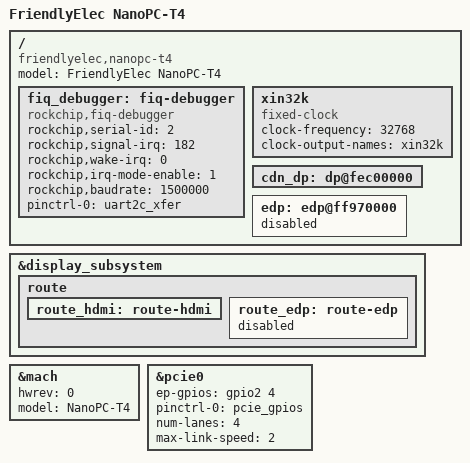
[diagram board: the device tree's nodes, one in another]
/*
 * Copyright (c) 2018 FriendlyElec Computer Tech. Co., Ltd.
 * (http://www.friendlyarm.com)
 *
 * This program is free software; you can redistribute it and/or
 * modify it under the terms of the GNU General Public License
 * as published by the Free Software Foundation; either version 2
 * of the License, or (at your option) any later version.
 *
 * This program is distributed in the hope that it will be useful,
 * but WITHOUT ANY WARRANTY; without even the implied warranty of
 * MERCHANTABILITY or FITNESS FOR A PARTICULAR PURPOSE.  See the
 * GNU General Public License for more details.
 *
 * You should have received a copy of the GNU General Public License
 * along with this program.  If not, see <http://www.gnu.org/licenses/>.
 */

/dts-v1/;
#include "rk3399-nanopi4-common.dtsi"

/ {
	model = "FriendlyElec NanoPC-T4";
	compatible = "friendlyelec,nanopc-t4", "rockchip,rk3399";

	fiq_debugger: fiq-debugger {
		compatible = "rockchip,fiq-debugger";
		rockchip,serial-id = <2>;
		rockchip,signal-irq = <182>;
		rockchip,wake-irq = <0>;
		rockchip,irq-mode-enable = <1>;  /* If enable uart uses irq instead of fiq */
		rockchip,baudrate = <1500000>;  /* Only 115200 and 1500000 */
		pinctrl-names = "default";
		pinctrl-0 = <&uart2c_xfer>;
	};

	xin32k: xin32k {
		compatible = "fixed-clock";
		clock-frequency = <32768>;
		clock-output-names = "xin32k";
		#clock-cells = <0>;
	};

	cdn_dp: dp@fec00000 {
		status = "okay";
	};

	edp: edp@ff970000 {
		status = "disabled";
		/delete-node/ edp_hpd;
	};

};

&display_subsystem {

	route {
		route_hdmi: route-hdmi {
			status = "okay";
		};
		
		route_edp: route-edp {
			status = "disabled";
		};
	};

};

&mach {
	hwrev = <0>;
	model = "NanoPC-T4";
};

&pcie0 {
	ep-gpios = <&gpio2 4 GPIO_ACTIVE_HIGH>;
	pinctrl-names = "default";
	pinctrl-0 = <&pcie_gpios>;
	num-lanes = <4>;
	max-link-speed = <2>;
};


&edp {
	status = "disabled";
};

&cdn_dp {
	status = "okay";
};

